# f29h85x_hsm_error_aggregator_config_regs register map
Vendor: Texas Instruments
Peripheral module from a debugger description file (folder HSM).
Registers are 32-bit, read-only, no defined reset value unless marked. A register's access mark holds for its fields unless they carry their own. Offsets are as the file gives them; lines under a group give offsets from that group; [hi:lo] are bit positions; {n}, {i} and the like mark numbered series; 'fields as' and 'values as' point back to an identical list; <NAME> marks a mode.

## HSM_ERROR_AGGREGATOR_CONFIG_REGS — HSM ERROR AGGREGATOR CONFIG Registers
0x00 HSM_HIGHPRIO_ERROR_ADDRESS — High Priority Error address register
  [31:0] HSM_HIGHPRIO_ERROR_ADDRESS — Address at which first High priority error occurred
0x04 HSM_LOWPRIO_ERROR_ADDRESS — Low Priority Error address register
  [31:0] HSM_LOWPRIO_ERROR_ADDRESS — Address at which first Low priority error occurred
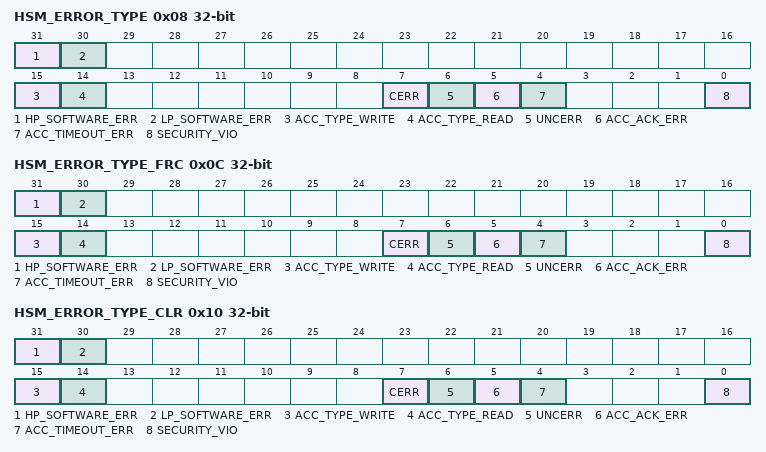
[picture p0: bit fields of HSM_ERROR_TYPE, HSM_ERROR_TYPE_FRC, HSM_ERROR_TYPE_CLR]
0x08 HSM_ERROR_TYPE — Error Type Register
  [31] HP_SOFTWARE_ERR — High Priority error set by software
  [30] LP_SOFTWARE_ERR — Low Priority error set by software
  [15] ACC_TYPE_WRITE — Access type write
  [14] ACC_TYPE_READ — Access type Read
  [7] CERR — Correctable error
  [6] UNCERR — Uncorrectable error
  [5] ACC_ACK_ERR — Access ACK error
  [4] ACC_TIMEOUT_ERR — Access timeout error
  [0] SECURITY_VIO — Security violation
0x0C HSM_ERROR_TYPE_FRC rw — Error Type Force Register
  [31] HP_SOFTWARE_ERR — Force high priority software error
  [30] LP_SOFTWARE_ERR — Force low priority software error
  [15] ACC_TYPE_WRITE — Access type write force
  [14] ACC_TYPE_READ — Access type Read force
  [7] CERR — Correctable error force
  [6] UNCERR — Uncorrectable error force
  [5] ACC_ACK_ERR — Access ACK error force
  [4] ACC_TIMEOUT_ERR — Access timeout error force
  [0] SECURITY_VIO — Security violation force
0x10 HSM_ERROR_TYPE_CLR rw — Error Type Clear Register
  [31] HP_SOFTWARE_ERR — clear high priority software error
  [30] LP_SOFTWARE_ERR — clear low priority software error
  [15] ACC_TYPE_WRITE — Access type write clear
  [14] ACC_TYPE_READ — Access type Read clear
  [7] CERR — Correctable error clear
  [6] UNCERR — Uncorrectable error clear
  [5] ACC_ACK_ERR — Access ACK error clear
  [4] ACC_TIMEOUT_ERR — Access timeout error clear
  [0] SECURITY_VIO — Security violation clear
